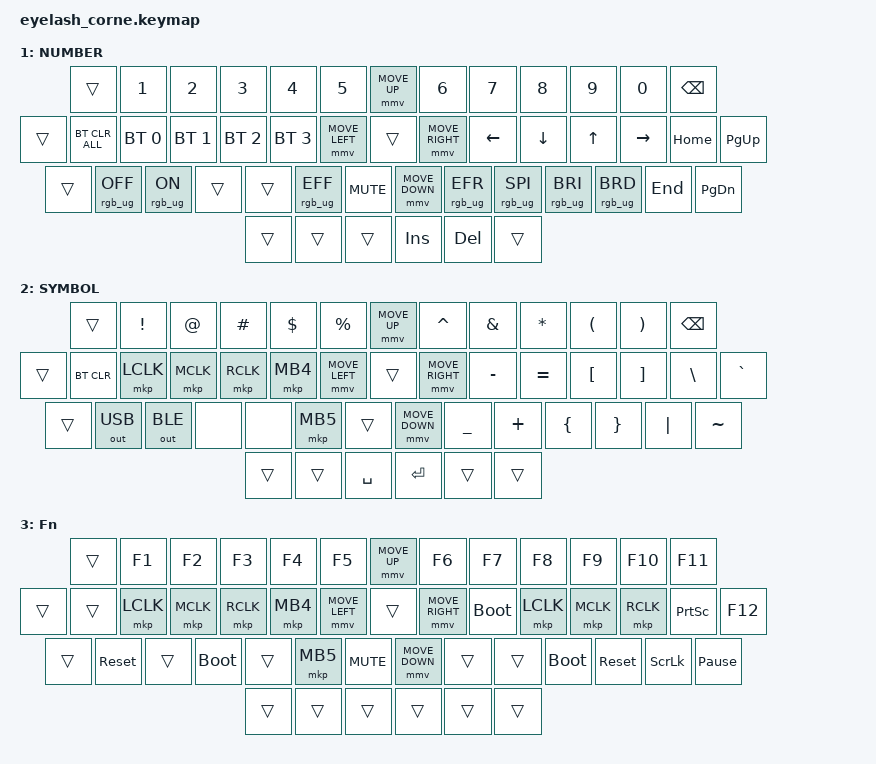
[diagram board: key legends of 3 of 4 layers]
#include <behaviors.dtsi>
#include <dt-bindings/zmk/bt.h>
#include <dt-bindings/zmk/keys.h>
#include <dt-bindings/zmk/mouse.h>
#include <dt-bindings/zmk/outputs.h>
#include <dt-bindings/zmk/rgb.h>

/ {
    behaviors {
        td0: td0 {
            compatible = "zmk,behavior-tap-dance";
            #binding-cells = <0>;
            bindings = <&kp LEFT_SHIFT>, <&kp CAPS>;
        };
    };

    rgb_encoder: rgb_encoder {
        compatible = "zmk,behavior-sensor-rotate";
        #sensor-binding-cells = <0>;
        bindings = <&rgb_ug RGB_BRI>, <&rgb_ug RGB_BRD>;
    };

    keymap {
        compatible = "zmk,keymap";

        default_layer {
            display-name = "QWERTY";

            bindings = <
&kp TAB    &kp Q  &kp W  &kp E  &kp R  &kp T                               &kp UP      &kp Y  &kp U  &kp I  &kp O  &kp P  &kp BSPC
&kp LCTRL  &kp LGUI A  &kp LALT S  &kp LCTRL D  &kp LSHFT F  &kp G          &kp LEFT  &kp BSPC  &kp RIGHT  &kp H  &kp RSHFT J  &kp RCTRL K  &kp RALT L  &kp RGUI SEMI  &kp BSLH
&kp ESC    &kp Z  &kp X  &kp C  &kp V  &kp B  &kp SPACE           &kp DOWN    &kp N  &kp M  &kp COMMA  &kp DOT  &kp FSLH  &kp SQT
                           &lt 1 SPACE  &kp DEL  &trans  &lt 2 ENTER  &mo 3  &trans
            >;

            sensor-bindings = <&inc_dec_kp C_VOLUME_UP C_VOLUME_DOWN>;
        };

        lower_layer {
            display-name = "NUMBER";
            bindings = <
&trans  &kp N1  &kp N2  &kp N3  &kp N4  &kp N5                         &mmv MOVE_UP    &kp N6  &kp N7  &kp N8  &kp N9  &kp N0  &kp BSPC
&trans  &bt BT_CLR_ALL  &bt BT_SEL 0  &bt BT_SEL 1  &bt BT_SEL 2  &bt BT_SEL 3  &mmv MOVE_LEFT  &trans  &mmv MOVE_RIGHT  &kp LEFT  &kp DOWN  &kp UP  &kp RIGHT  &kp HOME  &kp PG_UP
&trans  &rgb_ug RGB_OFF  &rgb_ug RGB_ON  &trans  &trans  &rgb_ug RGB_EFF  &kp C_MUTE  &mmv MOVE_DOWN  &rgb_ug RGB_EFR  &rgb_ug RGB_SPI  &rgb_ug RGB_BRI  &rgb_ug RGB_BRD  &kp END  &kp PG_DN
                                     &trans  &trans  &trans                                        &kp INS  &kp DEL  &trans
            >;

            sensor-bindings = <&inc_dec_kp PG_UP PG_DN>;
        };

        raise_layer {
            display-name = "SYMBOL";
            bindings = <
&trans  &kp EXCL  &kp AT  &kp HASH  &kp DLLR  &kp PRCNT                      &mmv MOVE_UP    &kp CARET  &kp AMPS  &kp ASTRK  &kp LPAR  &kp RPAR  &kp BSPC
&trans  &bt BT_CLR  &mkp LCLK  &mkp MCLK  &mkp RCLK  &mkp MB4  &mmv MOVE_LEFT  &trans  &mmv MOVE_RIGHT  &kp MINUS  &kp EQUAL  &kp LBKT  &kp RBKT  &kp BSLH  &kp GRAVE
&trans  &out OUT_USB  &out OUT_BLE  &none  &none  &mkp MB5  &trans  &mmv MOVE_DOWN  &kp UNDER  &kp PLUS  &kp LBRC  &kp RBRC  &kp PIPE  &kp TILDE
                                     &trans  &trans  &kp SPACE                            &kp RET  &trans  &trans
            >;

            sensor-bindings = <&inc_dec_kp PG_UP PG_DN>;
        };

        layer_3 {
            display-name = "Fn";
            bindings = <
&trans  &kp F1  &kp F2  &kp F3  &kp F4  &kp F5                        &mmv MOVE_UP    &kp F6  &kp F7  &kp F8  &kp F9  &kp F10  &kp F11
&trans  &trans  &mkp LCLK  &mkp MCLK  &mkp RCLK  &mkp MB4  &mmv MOVE_LEFT  &trans  &mmv MOVE_RIGHT  &bootloader  &mkp LCLK  &mkp MCLK  &mkp RCLK  &kp PRINTSCREEN  &kp F12
&trans  &sys_reset  &trans  &bootloader  &trans  &mkp MB5  &kp C_MUTE  &mmv MOVE_DOWN  &trans  &trans  &bootloader  &sys_reset  &kp SCROLLLOCK  &kp PAUSE_BREAK
                                     &trans  &trans  &trans                                      &trans  &trans  &trans
            >;

            sensor-bindings = <&rgb_encoder>;
        };
    };
};
